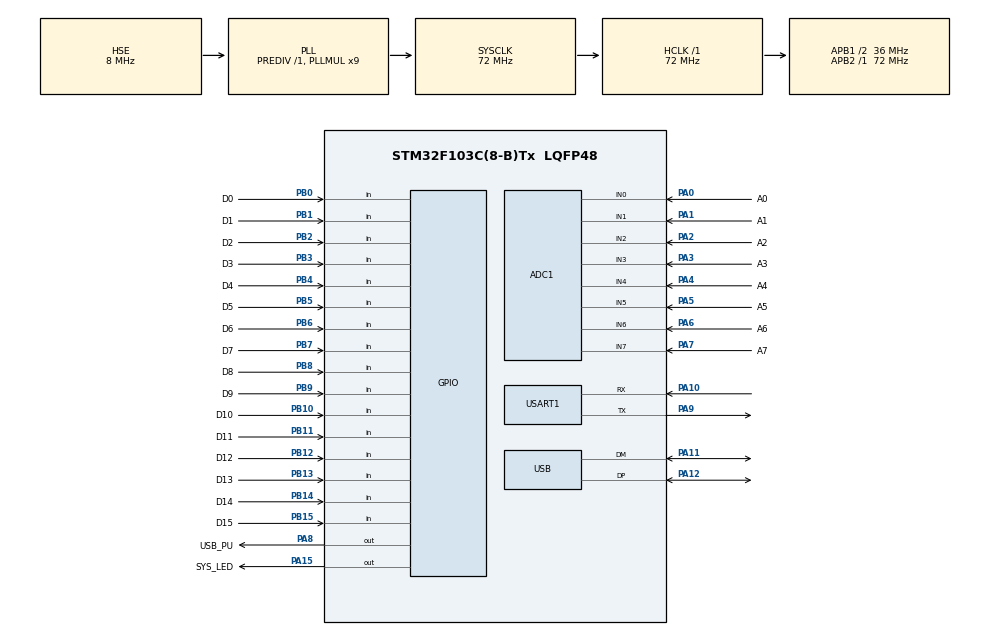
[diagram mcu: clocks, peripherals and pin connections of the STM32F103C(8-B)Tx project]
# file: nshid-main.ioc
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ADC1.Channel-0\#ChannelRegularConversion=ADC_CHANNEL_0
ADC1.NbrOfConversionFlag=1
ADC1.Rank-0\#ChannelRegularConversion=1
ADC1.SamplingTime-0\#ChannelRegularConversion=ADC_SAMPLETIME_1CYCLE_5
ADC1.master=1
Mcu.Family=STM32F1
Mcu.Name=STM32F103C(8-B)Tx
Mcu.Package=LQFP48
NVIC.PriorityGroup=NVIC_PRIORITYGROUP_4
NVIC.USB_LP_CAN1_RX0_IRQn=true\:0\:0\:false\:false\:true\:false\:true
PA0-WKUP.GPIO_Label=A0
PA0-WKUP.Signal=ADCx_IN0
PA1.GPIO_Label=A1
PA1.Signal=ADCx_IN1
PA10.Mode=Asynchronous
PA10.Signal=USART1_RX
PA11.Mode=Device
PA11.Signal=USB_DM
PA12.Mode=Device
PA12.Signal=USB_DP
PA13.Mode=Serial_Wire
PA13.Signal=SYS_JTMS-SWDIO
PA14.Mode=Serial_Wire
PA14.Signal=SYS_JTCK-SWCLK
PA15.GPIO_Label=SYS_LED
PA15.Signal=GPIO_Output
PA2.GPIO_Label=A2
PA2.Signal=ADCx_IN2
PA3.GPIO_Label=A3
PA3.Signal=ADCx_IN3
PA4.GPIO_Label=A4
PA4.Signal=ADCx_IN4
PA5.GPIO_Label=A5
PA5.Signal=ADCx_IN5
PA6.GPIO_Label=A6
PA6.Signal=ADCx_IN6
PA7.GPIO_Label=A7
PA7.Signal=ADCx_IN7
PA8.GPIO_Label=USB_PU
PA8.Signal=GPIO_Output
PA9.Mode=Asynchronous
PA9.Signal=USART1_TX
PB0.GPIO_Label=D0
PB0.Signal=GPIO_Input
PB1.GPIO_Label=D1
PB1.Signal=GPIO_Input
PB10.GPIO_Label=D10
PB10.Signal=GPIO_Input
PB11.GPIO_Label=D11
PB11.Signal=GPIO_Input
PB12.GPIO_Label=D12
PB12.Signal=GPIO_Input
PB13.GPIO_Label=D13
PB13.Signal=GPIO_Input
PB14.GPIO_Label=D14
PB14.Signal=GPIO_Input
PB15.GPIO_Label=D15
PB15.Signal=GPIO_Input
PB2.GPIO_Label=D2
PB2.Signal=GPIO_Input
PB3.GPIO_Label=D3
PB3.Signal=GPIO_Input
PB4.GPIO_Label=D4
PB4.Signal=GPIO_Input
PB5.GPIO_Label=D5
PB5.Signal=GPIO_Input
PB6.GPIO_Label=D6
PB6.Signal=GPIO_Input
PB7.GPIO_Label=D7
PB7.Signal=GPIO_Input
PB8.GPIO_Label=D8
PB8.Signal=GPIO_Input
PB9.GPIO_Label=D9
PB9.Signal=GPIO_Input
PD0-OSC_IN.Mode=HSE-External-Oscillator
PD0-OSC_IN.Signal=RCC_OSC_IN
PD1-OSC_OUT.Mode=HSE-External-Oscillator
PD1-OSC_OUT.Signal=RCC_OSC_OUT
ProjectManager.HeapSize=0x200
ProjectManager.StackSize=0x400
ProjectManager.TargetToolchain=STM32CubeIDE
RCC.ADCPresc=RCC_ADCPCLK2_DIV6
RCC.AHBFreq_Value=72000000
RCC.APB1CLKDivider=RCC_HCLK_DIV2
RCC.APB1Freq_Value=36000000
RCC.APB1TimFreq_Value=72000000
RCC.APB2Freq_Value=72000000
RCC.APB2TimFreq_Value=72000000
RCC.HCLKFreq_Value=72000000
RCC.PLLMUL=RCC_PLL_MUL9
RCC.SYSCLKFreq_VALUE=72000000
RCC.SYSCLKSource=RCC_SYSCLKSOURCE_PLLCLK
RCC.USBFreq_Value=48000000
RCC.USBPrescaler=RCC_USBCLKSOURCE_PLL_DIV1_5
SH.ADCx_IN0.0=ADC1_IN0,IN0
SH.ADCx_IN1.0=ADC1_IN1,IN1
SH.ADCx_IN2.0=ADC1_IN2,IN2
SH.ADCx_IN3.0=ADC1_IN3,IN3
SH.ADCx_IN4.0=ADC1_IN4,IN4
SH.ADCx_IN5.0=ADC1_IN5,IN5
SH.ADCx_IN6.0=ADC1_IN6,IN6
SH.ADCx_IN7.0=ADC1_IN7,IN7
USART1.VirtualMode=VM_ASYNC
USB_DEVICE.CLASS_NAME_FS=HID
USB_DEVICE.MANUFACTURER_STRING=NSDN
USB_DEVICE.VID=12850
USB_DEVICE.VirtualMode=Hid
USB_DEVICE.VirtualModeFS=Hid_FS
VP_USB_DEVICE_VS_USB_DEVICE_HID_FS.Mode=HID_FS
board=custom

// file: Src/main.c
/* USER CODE BEGIN Header */
/**
  ******************************************************************************
  * @file           : main.c
  * @brief          : Main program body
  ******************************************************************************
  * @attention
  *
  * <h2><center>&copy; Copyright (c) 2020 STMicroelectronics.
  * All rights reserved.</center></h2>
  *
  * This software component is licensed by ST under Ultimate Liberty license
  * SLA0044, the "License"; You may not use this file except in compliance with
  * the License. You may obtain a copy of the License at:
  *                             www.st.com/SLA0044
  *
  ******************************************************************************
  */
/* USER CODE END Header */
#include "main.h"
#include "usb_device.h"

ADC_HandleTypeDef hadc1;

UART_HandleTypeDef huart1;

/* USER CODE BEGIN PV */
/* Private variables ---------------------------------------------------------*/

/* USER CODE END PV */

void SystemClock_Config(void);
static void MX_GPIO_Init(void);
static void MX_USART1_UART_Init(void);
static void MX_ADC1_Init(void);
/* USER CODE BEGIN PFP */
/* Private function prototypes -----------------------------------------------*/

/* USER CODE END PFP */

int main(void)
{

  /* MCU Configuration--------------------------------------------------------*/

  /* Reset of all peripherals, Initializes the Flash interface and the Systick. */
  HAL_Init();

  /* Configure the system clock */
  SystemClock_Config();

  /* Initialize all configured peripherals */
  MX_GPIO_Init();
  MX_USART1_UART_Init();
  MX_ADC1_Init();
  MX_USB_DEVICE_Init();
  /* USER CODE BEGIN 2 */
  HAL_Delay(500);
  HAL_GPIO_WritePin(USB_PU_GPIO_Port, USB_PU_Pin, GPIO_PIN_SET);
  /* USER CODE END 2 */

  /* Infinite loop */
  while (1)
  {

  }
}

void SystemClock_Config(void)
{
  RCC_OscInitTypeDef RCC_OscInitStruct = {0};
  RCC_ClkInitTypeDef RCC_ClkInitStruct = {0};
  RCC_PeriphCLKInitTypeDef PeriphClkInit = {0};

  /** Initializes the RCC Oscillators according to the specified parameters
  * in the RCC_OscInitTypeDef structure.
  */
  RCC_OscInitStruct.OscillatorType = RCC_OSCILLATORTYPE_HSE;
  RCC_OscInitStruct.HSEState = RCC_HSE_ON;
  RCC_OscInitStruct.HSEPredivValue = RCC_HSE_PREDIV_DIV1;
  RCC_OscInitStruct.HSIState = RCC_HSI_ON;
  RCC_OscInitStruct.PLL.PLLState = RCC_PLL_ON;
  RCC_OscInitStruct.PLL.PLLSource = RCC_PLLSOURCE_HSE;
  RCC_OscInitStruct.PLL.PLLMUL = RCC_PLL_MUL9;
  if (HAL_RCC_OscConfig(&RCC_OscInitStruct) != HAL_OK)
  {
    Error_Handler();
  }
  /** Initializes the CPU, AHB and APB buses clocks
  */
  RCC_ClkInitStruct.ClockType = RCC_CLOCKTYPE_HCLK|RCC_CLOCKTYPE_SYSCLK
                              |RCC_CLOCKTYPE_PCLK1|RCC_CLOCKTYPE_PCLK2;
  RCC_ClkInitStruct.SYSCLKSource = RCC_SYSCLKSOURCE_PLLCLK;
  RCC_ClkInitStruct.AHBCLKDivider = RCC_SYSCLK_DIV1;
  RCC_ClkInitStruct.APB1CLKDivider = RCC_HCLK_DIV2;
  RCC_ClkInitStruct.APB2CLKDivider = RCC_HCLK_DIV1;

  if (HAL_RCC_ClockConfig(&RCC_ClkInitStruct, FLASH_LATENCY_2) != HAL_OK)
  {
    Error_Handler();
  }
  PeriphClkInit.PeriphClockSelection = RCC_PERIPHCLK_ADC|RCC_PERIPHCLK_USB;
  PeriphClkInit.AdcClockSelection = RCC_ADCPCLK2_DIV6;
  PeriphClkInit.UsbClockSelection = RCC_USBCLKSOURCE_PLL_DIV1_5;
  if (HAL_RCCEx_PeriphCLKConfig(&PeriphClkInit) != HAL_OK)
  {
    Error_Handler();
  }
}

static void MX_ADC1_Init(void)
{

  ADC_ChannelConfTypeDef sConfig = {0};

  /** Common config
  */
  hadc1.Instance = ADC1;
  hadc1.Init.ScanConvMode = ADC_SCAN_DISABLE;
  hadc1.Init.ContinuousConvMode = DISABLE;
  hadc1.Init.DiscontinuousConvMode = DISABLE;
  hadc1.Init.ExternalTrigConv = ADC_SOFTWARE_START;
  hadc1.Init.DataAlign = ADC_DATAALIGN_RIGHT;
  hadc1.Init.NbrOfConversion = 1;
  if (HAL_ADC_Init(&hadc1) != HAL_OK)
  {
    Error_Handler();
  }
  /** Configure Regular Channel
  */
  sConfig.Channel = ADC_CHANNEL_0;
  sConfig.Rank = ADC_REGULAR_RANK_1;
  sConfig.SamplingTime = ADC_SAMPLETIME_1CYCLE_5;
  if (HAL_ADC_ConfigChannel(&hadc1, &sConfig) != HAL_OK)
  {
    Error_Handler();
  }

}

static void MX_USART1_UART_Init(void)
{

  huart1.Instance = USART1;
  huart1.Init.BaudRate = 115200;
  huart1.Init.WordLength = UART_WORDLENGTH_8B;
  huart1.Init.StopBits = UART_STOPBITS_1;
  huart1.Init.Parity = UART_PARITY_NONE;
  huart1.Init.Mode = UART_MODE_TX_RX;
  huart1.Init.HwFlowCtl = UART_HWCONTROL_NONE;
  huart1.Init.OverSampling = UART_OVERSAMPLING_16;
  if (HAL_UART_Init(&huart1) != HAL_OK)
  {
    Error_Handler();
  }

}

static void MX_GPIO_Init(void)
{
  GPIO_InitTypeDef GPIO_InitStruct = {0};

  /* GPIO Ports Clock Enable */
  __HAL_RCC_GPIOD_CLK_ENABLE();
  __HAL_RCC_GPIOA_CLK_ENABLE();
  __HAL_RCC_GPIOB_CLK_ENABLE();

  /*Configure GPIO pin Output Level */
  HAL_GPIO_WritePin(GPIOA, USB_PU_Pin|SYS_LED_Pin, GPIO_PIN_RESET);

  /*Configure GPIO pins : D0_Pin D1_Pin D2_Pin D10_Pin
                           D11_Pin D12_Pin D13_Pin D14_Pin
                           D15_Pin D3_Pin D4_Pin D5_Pin
                           D6_Pin D7_Pin D8_Pin D9_Pin */
  GPIO_InitStruct.Pin = D0_Pin|D1_Pin|D2_Pin|D10_Pin
                          |D11_Pin|D12_Pin|D13_Pin|D14_Pin
                          |D15_Pin|D3_Pin|D4_Pin|D5_Pin
                          |D6_Pin|D7_Pin|D8_Pin|D9_Pin;
  GPIO_InitStruct.Mode = GPIO_MODE_INPUT;
  GPIO_InitStruct.Pull = GPIO_NOPULL;
  HAL_GPIO_Init(GPIOB, &GPIO_InitStruct);

  /*Configure GPIO pins : USB_PU_Pin SYS_LED_Pin */
  GPIO_InitStruct.Pin = USB_PU_Pin|SYS_LED_Pin;
  GPIO_InitStruct.Mode = GPIO_MODE_OUTPUT_PP;
  GPIO_InitStruct.Pull = GPIO_NOPULL;
  GPIO_InitStruct.Speed = GPIO_SPEED_FREQ_LOW;
  HAL_GPIO_Init(GPIOA, &GPIO_InitStruct);

}

void Error_Handler(void)
{
  while(1)
  {
  }
}

/************************ (C) COPYRIGHT STMicroelectronics *****END OF FILE****/
